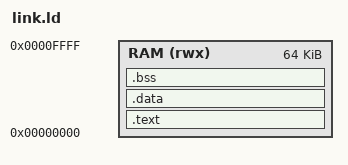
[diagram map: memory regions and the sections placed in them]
MEMORY
{
    RAM (rwx) : ORIGIN = 0x0000, LENGTH = 64K
}

SECTIONS
{
    .text : {
        *(.text)
    } > RAM

    .data : {
        *(.data)
    } > RAM

    .bss : {
        *(.bss)
    } > RAM
}
